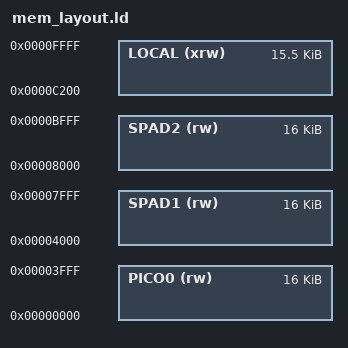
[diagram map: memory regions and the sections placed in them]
MEMORY
{
	PICO0 (rw) : ORIGIN = 0x00000000, LENGTH = 0x004000
	SPAD1 (rw) : ORIGIN = 0x00004000, LENGTH = 0x004000
	SPAD2 (rw) : ORIGIN = 0x00008000, LENGTH = 0x004000
	LOCAL (xrw) : ORIGIN = 0x0000c200, LENGTH = 0x003E00
}
